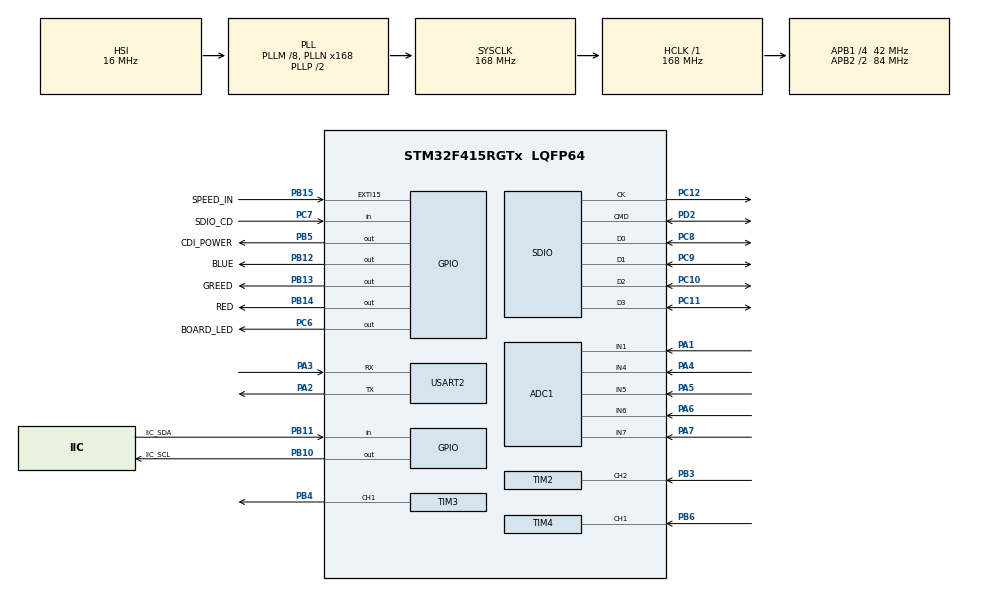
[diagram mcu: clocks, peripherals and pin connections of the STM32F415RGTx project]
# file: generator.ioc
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ADC1.Channel-0\#ChannelRegularConversion=ADC_CHANNEL_1
ADC1.Channel-1\#ChannelRegularConversion=ADC_CHANNEL_4
ADC1.Channel-2\#ChannelRegularConversion=ADC_CHANNEL_5
ADC1.Channel-3\#ChannelRegularConversion=ADC_CHANNEL_6
ADC1.Channel-9\#ChannelRegularConversion=ADC_CHANNEL_7
ADC1.ContinuousConvMode=ENABLE
ADC1.DMAContinuousRequests=ENABLE
ADC1.InjNumberOfConversion=0
ADC1.NbrOfConversion=5
ADC1.NbrOfConversionFlag=1
ADC1.Rank-0\#ChannelRegularConversion=1
ADC1.Rank-1\#ChannelRegularConversion=2
ADC1.Rank-2\#ChannelRegularConversion=3
ADC1.Rank-3\#ChannelRegularConversion=4
ADC1.Rank-9\#ChannelRegularConversion=5
ADC1.SamplingTime-0\#ChannelRegularConversion=ADC_SAMPLETIME_28CYCLES
ADC1.SamplingTime-1\#ChannelRegularConversion=ADC_SAMPLETIME_28CYCLES
ADC1.SamplingTime-2\#ChannelRegularConversion=ADC_SAMPLETIME_28CYCLES
ADC1.SamplingTime-3\#ChannelRegularConversion=ADC_SAMPLETIME_28CYCLES
ADC1.SamplingTime-9\#ChannelRegularConversion=ADC_SAMPLETIME_28CYCLES
ADC1.master=1
Dma.ADC1.0.Direction=DMA_PERIPH_TO_MEMORY
Dma.ADC1.0.FIFOMode=DMA_FIFOMODE_DISABLE
Dma.ADC1.0.Instance=DMA2_Stream0
Dma.ADC1.0.MemDataAlignment=DMA_MDATAALIGN_HALFWORD
Dma.ADC1.0.MemInc=DMA_MINC_ENABLE
Dma.ADC1.0.Mode=DMA_CIRCULAR
Dma.ADC1.0.PeriphDataAlignment=DMA_PDATAALIGN_HALFWORD
Dma.ADC1.0.PeriphInc=DMA_PINC_DISABLE
Dma.ADC1.0.Priority=DMA_PRIORITY_LOW
Dma.Request0=ADC1
Dma.Request1=SDIO_RX
Dma.Request2=SDIO_TX
Dma.SDIO_RX.1.Direction=DMA_PERIPH_TO_MEMORY
Dma.SDIO_RX.1.FIFOMode=DMA_FIFOMODE_ENABLE
Dma.SDIO_RX.1.FIFOThreshold=DMA_FIFO_THRESHOLD_FULL
Dma.SDIO_RX.1.Instance=DMA2_Stream3
Dma.SDIO_RX.1.MemBurst=DMA_MBURST_INC4
Dma.SDIO_RX.1.MemDataAlignment=DMA_MDATAALIGN_WORD
Dma.SDIO_RX.1.MemInc=DMA_MINC_ENABLE
Dma.SDIO_RX.1.Mode=DMA_PFCTRL
Dma.SDIO_RX.1.PeriphBurst=DMA_PBURST_INC4
Dma.SDIO_RX.1.PeriphDataAlignment=DMA_PDATAALIGN_WORD
Dma.SDIO_RX.1.PeriphInc=DMA_PINC_DISABLE
Dma.SDIO_RX.1.Priority=DMA_PRIORITY_LOW
Dma.SDIO_TX.2.Direction=DMA_MEMORY_TO_PERIPH
Dma.SDIO_TX.2.FIFOMode=DMA_FIFOMODE_ENABLE
Dma.SDIO_TX.2.FIFOThreshold=DMA_FIFO_THRESHOLD_FULL
Dma.SDIO_TX.2.Instance=DMA2_Stream6
Dma.SDIO_TX.2.MemBurst=DMA_MBURST_INC4
Dma.SDIO_TX.2.MemDataAlignment=DMA_MDATAALIGN_WORD
Dma.SDIO_TX.2.MemInc=DMA_MINC_ENABLE
Dma.SDIO_TX.2.Mode=DMA_PFCTRL
Dma.SDIO_TX.2.PeriphBurst=DMA_PBURST_INC4
Dma.SDIO_TX.2.PeriphDataAlignment=DMA_PDATAALIGN_WORD
Dma.SDIO_TX.2.PeriphInc=DMA_PINC_DISABLE
Dma.SDIO_TX.2.Priority=DMA_PRIORITY_LOW
FATFS.BSP.number=1
FATFS._CODE_PAGE=936
FATFS._USE_LFN=2
FATFS0.BSP.STBoard=false
FATFS0.BSP.api=Unknown
FATFS0.BSP.i2caddr=0
FATFS0.BSP.instance=PC7
FATFS0.BSP.ip=GPIO
FATFS0.BSP.mode=Input
FATFS0.BSP.name=Detect_SDIO
FATFS0.BSP.solution=PC7
Mcu.Family=STM32F4
Mcu.Name=STM32F415RGTx
Mcu.Package=LQFP64
NVIC.ADC_IRQn=true\:0\:0\:false\:false\:true\:true\:true
NVIC.DMA2_Stream0_IRQn=true\:0\:0\:false\:false\:true\:false\:true
NVIC.DMA2_Stream3_IRQn=true\:0\:0\:false\:false\:true\:false\:true
NVIC.DMA2_Stream6_IRQn=true\:0\:0\:false\:false\:true\:false\:true
NVIC.EXTI15_10_IRQn=true\:0\:0\:false\:false\:true\:true\:true
NVIC.PriorityGroup=NVIC_PRIORITYGROUP_4
NVIC.SDIO_IRQn=true\:0\:0\:false\:false\:true\:true\:true
NVIC.TIM2_IRQn=true\:0\:0\:false\:false\:true\:true\:true
NVIC.TIM4_IRQn=true\:0\:0\:false\:false\:true\:true\:true
NVIC.TIM7_IRQn=true\:0\:0\:false\:false\:true\:true\:true
NVIC.USART2_IRQn=true\:0\:0\:false\:false\:true\:true\:true
PA1.Signal=ADCx_IN1
PA13.Mode=Serial_Wire
PA13.Signal=SYS_JTMS-SWDIO
PA14.Mode=Serial_Wire
PA14.Signal=SYS_JTCK-SWCLK
PA2.Mode=Asynchronous
PA2.Signal=USART2_TX
PA3.Mode=Asynchronous
PA3.Signal=USART2_RX
PA4.Signal=ADCx_IN4
PA5.Signal=ADCx_IN5
PA6.Signal=ADCx_IN6
PA7.Signal=ADCx_IN7
PB10.GPIO_Label=IIC_SCL
PB10.Signal=GPIO_Output
PB11.GPIO_Label=IIC_SDA
PB11.Signal=GPIO_Input
PB12.GPIO_Label=BLUE
PB12.Signal=GPIO_Output
PB13.GPIO_Label=GREED
PB13.Signal=GPIO_Output
PB14.GPIO_Label=RED
PB14.Signal=GPIO_Output
PB15.GPIO_Label=SPEED_IN
PB15.Signal=GPXTI15
PB3.Signal=S_TIM2_CH2
PB4.Signal=S_TIM3_CH1
PB5.GPIO_Label=CDI_POWER
PB5.Signal=GPIO_Output
PB6.Signal=S_TIM4_CH1
PC10.Mode=SD_4_bits_Wide_bus
PC10.Signal=SDIO_D2
PC11.Mode=SD_4_bits_Wide_bus
PC11.Signal=SDIO_D3
PC12.Mode=SD_4_bits_Wide_bus
PC12.Signal=SDIO_CK
PC6.GPIO_Label=BOARD_LED
PC6.Signal=GPIO_Output
PC7.GPIO_Label=SDIO_CD
PC7.Signal=GPIO_Input
PC8.Mode=SD_4_bits_Wide_bus
PC8.Signal=SDIO_D0
PC9.Mode=SD_4_bits_Wide_bus
PC9.Signal=SDIO_D1
PD2.Mode=SD_4_bits_Wide_bus
PD2.Signal=SDIO_CMD
ProjectManager.HeapSize=0x4000
ProjectManager.StackSize=0xC000
ProjectManager.TargetToolchain=MDK-ARM V5.27
RCC.48MHZClocksFreq_Value=48000000
RCC.AHBFreq_Value=168000000
RCC.APB1CLKDivider=RCC_HCLK_DIV4
RCC.APB1Freq_Value=42000000
RCC.APB1TimFreq_Value=84000000
RCC.APB2CLKDivider=RCC_HCLK_DIV2
RCC.APB2Freq_Value=84000000
RCC.APB2TimFreq_Value=168000000
RCC.CortexFreq_Value=168000000
RCC.HCLKFreq_Value=168000000
RCC.HSE_VALUE=25000000
RCC.HSI_VALUE=16000000
RCC.LSE_VALUE=32768
RCC.PLLM=8
RCC.PLLN=168
RCC.PLLQ=7
RCC.SYSCLKFreq_VALUE=168000000
RCC.SYSCLKSource=RCC_SYSCLKSOURCE_PLLCLK
RCC.VCOOutputFreq_Value=336000000
SH.ADCx_IN1.0=ADC1_IN1,IN1
SH.ADCx_IN4.0=ADC1_IN4,IN4
SH.ADCx_IN5.0=ADC1_IN5,IN5
SH.ADCx_IN6.0=ADC1_IN6,IN6
SH.ADCx_IN7.0=ADC1_IN7,IN7
SH.S_TIM2_CH2.0=TIM2_CH2,Input_Capture2_from_TI2
SH.S_TIM2_CH2.1=TIM2_CH2,Input_Capture1_from_TI2
SH.S_TIM2_CH2.2=TIM2_CH2,TriggerSource_TI2FP2
SH.S_TIM3_CH1.0=TIM3_CH1,PWM Generation1 CH1
SH.S_TIM4_CH1.0=TIM4_CH1,Input_Capture1_from_TI1
SH.S_TIM4_CH1.1=TIM4_CH1,Input_Capture2_from_TI1
SH.S_TIM4_CH1.2=TIM4_CH1,TriggerSource_TI1FP1
TIM2.Channel-Input_Capture1_from_TI2=TIM_CHANNEL_1
TIM2.Channel-Input_Capture2_from_TI2=TIM_CHANNEL_2
TIM2.ICPolarity_CH1=TIM_INPUTCHANNELPOLARITY_FALLING
TIM2.ICPolarity_CH2=TIM_INPUTCHANNELPOLARITY_RISING
TIM2.Prescaler=83
TIM3.Channel-PWM\ Generation1\ CH1=TIM_CHANNEL_1
TIM3.OCPolarity_1=TIM_OCPOLARITY_LOW
TIM3.Period=2000
TIM3.Prescaler=83
TIM3.Pulse-PWM\ Generation1\ CH1=150
TIM4.Channel-Input_Capture1_from_TI1=TIM_CHANNEL_1
TIM4.Channel-Input_Capture2_from_TI1=TIM_CHANNEL_2
TIM4.ICPolarity_CH2=TIM_INPUTCHANNELPOLARITY_FALLING
TIM4.Prescaler=83
TIM6.Period=50000
TIM6.Prescaler=839
TIM7.Period=50000
TIM7.Prescaler=83
USART2.VirtualMode=VM_ASYNC
VP_FATFS_VS_SDIO.Mode=SDIO
VP_TIM2_VS_ClockSourceINT.Mode=Internal
VP_TIM2_VS_ControllerModeReset.Mode=Reset Mode
VP_TIM4_VS_ClockSourceINT.Mode=Internal
VP_TIM4_VS_ControllerModeReset.Mode=Reset Mode
VP_TIM6_VS_ClockSourceINT.Mode=Enable_Timer
VP_TIM7_VS_ClockSourceINT.Mode=Enable_Timer
board=custom

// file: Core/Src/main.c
/* USER CODE BEGIN Header */
/**
  ******************************************************************************
  * @file           : main.c
  * @brief          : Main program body
  ******************************************************************************
  * @attention
  *
  * <h2><center>&copy; Copyright (c) 2020 STMicroelectronics.
  * All rights reserved.</center></h2>
  *
  * This software component is licensed by ST under Ultimate Liberty license
  * SLA0044, the "License"; You may not use this file except in compliance with
  * the License. You may obtain a copy of the License at:
  *                             www.st.com/SLA0044
  *
  ******************************************************************************
  */
/* USER CODE END Header */
#include "main.h"
#include "adc.h"
#include "dma.h"
#include "fatfs.h"
#include "sdio.h"
#include "tim.h"
#include "usart.h"
#include "gpio.h"
#include "exit.h"
#include "flash_internal.h"
#include "logger.h"

/* USER CODE BEGIN PV */
uint32_t loop_idx100ms=0;
uint32_t loop_idx500ms=0;

/* USER CODE END PV */

void SystemClock_Config(void);

int main(void)
{

  /* MCU Configuration--------------------------------------------------------*/

  /* Reset of all peripherals, Initializes the Flash interface and the Systick. */
  HAL_Init();

  /* Configure the system clock */
  SystemClock_Config();

  /* USER CODE BEGIN SysInit */
  SystemParameterRAMMapInit();
  /* USER CODE END SysInit */

  /* Initialize all configured peripherals */
  MX_GPIO_Init();
  MX_EXIT_Init();
  MX_DMA_Init();
  MX_ADC1_Init();
  MX_USART2_UART_Init();
  MX_SDIO_SD_Init();
  MX_TIM3_Init();
  MX_TIM6_Init();
  MX_TIM7_Init();
  MX_FATFS_Init();
  MX_TIM2_Init();
  MX_TIM4_Init();
  /* USER CODE BEGIN 2 */
  HAL_ADC_Start_DMA(&hadc1, (uint32_t*)&ADC_Value, 5);
  HAL_TIM_Base_Start_IT(&htim6);    //�򿪶�ʱ��
  HAL_TIM_Base_Start_IT(&htim7);    //�򿪶�ʱ��
  HAL_TIM_PWM_Start(&htim3,TIM_CHANNEL_1);
  HAL_TIM_IC_Start_IT(&htim2,TIM_CHANNEL_1);
  HAL_TIM_IC_Start_IT(&htim4,TIM_CHANNEL_2);
  Log_Init();
  SystemParameterSaveData(123,456);
  CheckSystemParameterSaveData();
  /* USER CODE END 2 */

  /* Infinite loop */
  /* USER CODE BEGIN WHILE */
  while (1)
  {
    while(!flag_10ms_timer){}
    flag_10ms_timer = 0;
    loop_idx100ms+=10;
    if(loop_idx100ms>=100)
    {
        loop_idx100ms=0;
        uint64_t _systime = GetMillis();
        ECU_Info _ecu_info;
        _ecu_info.voltage_set = ADC_Value[0];
        _ecu_info.voltage = ADC_Value[0];
        _ecu_info.current_used = ADC_Value[1];
        _ecu_info.current_charge = ADC_Value[2];
        _ecu_info.pwm_in_mode = pwm_in_mode;
        _ecu_info.pwm_in_throttle = pwm_in_throttle;
        _ecu_info.pwm_max_set = 2000;
        _ecu_info.pwm_min_set = 1000;
        _ecu_info.pwm_out_throttle = TIM3->CCR1;
        _ecu_info.servo_direction = 1;
        _ecu_info.motor_speed = 1500;
        Write_ECU(_systime,&_ecu_info);
    }
    loop_idx500ms+=10;
    if(loop_idx500ms>=500)
    {
        loop_idx500ms=0;
        HAL_GPIO_TogglePin(GPIOB, BLUE_Pin|GREED_Pin|RED_Pin);
    }

  }
  /* USER CODE END 3 */
}

void SystemClock_Config(void)
{
  RCC_OscInitTypeDef RCC_OscInitStruct = {0};
  RCC_ClkInitTypeDef RCC_ClkInitStruct = {0};

  /** Configure the main internal regulator output voltage
  */
  __HAL_RCC_PWR_CLK_ENABLE();
  __HAL_PWR_VOLTAGESCALING_CONFIG(PWR_REGULATOR_VOLTAGE_SCALE1);
  /** Initializes the RCC Oscillators according to the specified parameters
  * in the RCC_OscInitTypeDef structure.
  */
  RCC_OscInitStruct.OscillatorType = RCC_OSCILLATORTYPE_HSI;
  RCC_OscInitStruct.HSIState = RCC_HSI_ON;
  RCC_OscInitStruct.HSICalibrationValue = RCC_HSICALIBRATION_DEFAULT;
  RCC_OscInitStruct.PLL.PLLState = RCC_PLL_ON;
  RCC_OscInitStruct.PLL.PLLSource = RCC_PLLSOURCE_HSI;
  RCC_OscInitStruct.PLL.PLLM = 8;
  RCC_OscInitStruct.PLL.PLLN = 168;
  RCC_OscInitStruct.PLL.PLLP = RCC_PLLP_DIV2;
  RCC_OscInitStruct.PLL.PLLQ = 7;
  if (HAL_RCC_OscConfig(&RCC_OscInitStruct) != HAL_OK)
  {
    Error_Handler();
  }
  /** Initializes the CPU, AHB and APB buses clocks
  */
  RCC_ClkInitStruct.ClockType = RCC_CLOCKTYPE_HCLK|RCC_CLOCKTYPE_SYSCLK
                              |RCC_CLOCKTYPE_PCLK1|RCC_CLOCKTYPE_PCLK2;
  RCC_ClkInitStruct.SYSCLKSource = RCC_SYSCLKSOURCE_PLLCLK;
  RCC_ClkInitStruct.AHBCLKDivider = RCC_SYSCLK_DIV1;
  RCC_ClkInitStruct.APB1CLKDivider = RCC_HCLK_DIV4;
  RCC_ClkInitStruct.APB2CLKDivider = RCC_HCLK_DIV2;

  if (HAL_RCC_ClockConfig(&RCC_ClkInitStruct, FLASH_LATENCY_5) != HAL_OK)
  {
    Error_Handler();
  }
}

void Error_Handler(void)
{
}

/************************ (C) COPYRIGHT STMicroelectronics *****END OF FILE****/
